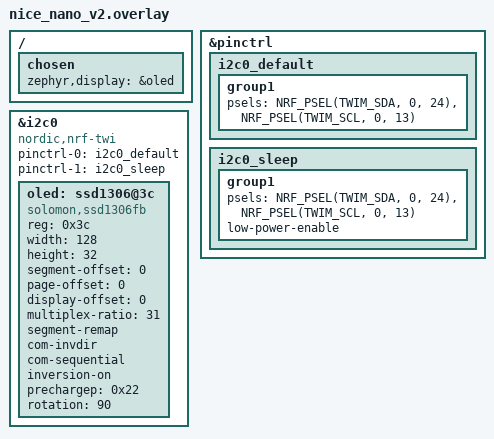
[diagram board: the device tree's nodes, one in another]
/*
 * Board-specific overlay for nice_nano_v2
 * Overrides I2C pins for custom OLED connection
 * This will apply when using the nice_oled shield
 */

#include <zephyr/dt-bindings/gpio/gpio.h>

/ {
    chosen {
        zephyr,display = &oled;
    };
};

// Override the pinctrl for I2C to use custom pins
&pinctrl {
    i2c0_default: i2c0_default {
        group1 {
            psels = <NRF_PSEL(TWIM_SDA, 0, 24)>,   /* P0.24 - SDA */
                    <NRF_PSEL(TWIM_SCL, 0, 13)>;   /* P0.13 - SCL */
        };
    };

    i2c0_sleep: i2c0_sleep {
        group1 {
            psels = <NRF_PSEL(TWIM_SDA, 0, 24)>,   /* P0.24 - SDA */
                    <NRF_PSEL(TWIM_SCL, 0, 13)>;   /* P0.13 - SCL */
            low-power-enable;
        };
    };
};

// Ensure I2C is properly configured with our custom pins
&i2c0 {
    compatible = "nordic,nrf-twi";
    status = "okay";
    pinctrl-0 = <&i2c0_default>;
    pinctrl-1 = <&i2c0_sleep>;
    pinctrl-names = "default", "sleep";

    oled: ssd1306@3c {
        compatible = "solomon,ssd1306fb";
        reg = <0x3c>;
        width = <128>;
        height = <32>;
        segment-offset = <0>;
        page-offset = <0>;
        display-offset = <0>;
        multiplex-ratio = <31>;
        segment-remap;
        com-invdir;
        com-sequential;
        inversion-on;
        prechargep = <0x22>;
        rotation = <90>;  // Rotate 90 degrees for horizontal orientation
    };
};
